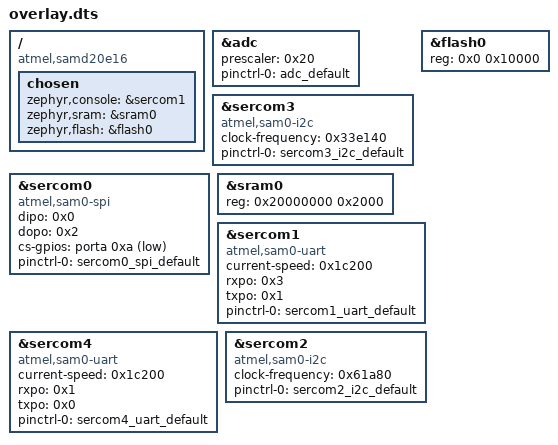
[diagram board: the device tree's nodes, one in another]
/ {
	compatible = "atmel,samd20e16", "atmel,samd20";
	chosen {
		zephyr,console = &sercom1;
		zephyr,sram = &sram0;
		zephyr,flash = &flash0;
	};
};
&adc{
	prescaler = < 0x20 >;
	status = "okay";
	#address-cells = < 0x1 >;
	#size-cells = < 0x0 >;
	pinctrl-0 = < &adc_default >;
	pinctrl-names = "default";
};
&sercom3{
	compatible = "atmel,sam0-i2c";
	status = "okay";
	clock-frequency = < 0x33e140 >;
	#address-cells = < 0x1 >;
	#size-cells = < 0x0 >;
	pinctrl-0 = < &sercom3_i2c_default >;
	pinctrl-names = "default";
};
&flash0{
	reg = < 0x0 0x10000 >;
};
&sercom0{
	compatible = "atmel,sam0-spi";
	status = "okay";
	dipo = < 0x0 >;
	dopo = < 0x2 >;
	#address-cells = < 0x1 >;
	#size-cells = < 0x0 >;
	cs-gpios = < &porta 0xa 0x1 >;
	pinctrl-0 = < &sercom0_spi_default >;
	pinctrl-names = "default";
};
&sram0{
	reg = < 0x20000000 0x2000 >;
};
&sercom1{
	compatible = "atmel,sam0-uart";
	status = "okay";
	current-speed = < 0x1c200 >;
	rxpo = < 0x3 >;
	txpo = < 0x1 >;
	pinctrl-0 = < &sercom1_uart_default >;
	pinctrl-names = "default";
};
&sercom4{
	compatible = "atmel,sam0-uart";
	status = "okay";
	current-speed = < 0x1c200 >;
	rxpo = < 0x1 >;
	txpo = < 0x0 >;
	pinctrl-0 = < &sercom4_uart_default >;
	pinctrl-names = "default";
};
&sercom2{
	compatible = "atmel,sam0-i2c";
	status = "okay";
	clock-frequency = < 0x61a80 >;
	#address-cells = < 0x1 >;
	#size-cells = < 0x0 >;
	pinctrl-0 = < &sercom2_i2c_default >;
	pinctrl-names = "default";
};
